# EFR32FG25A221F1920IM56 register map
Vendor: Silicon Labs; Series: EFR32; File version: B
Registers are 32-bit, read-write, reset 0x0 unless marked. A register's access mark holds for its fields unless they carry their own. Offsets are from the block's base; [hi:lo] are bit positions; {n}, {i} and the like mark numbered series.

## SMU_NS_CFGNS — SMU_NS_CFGNS Registers
Base 0x5400C000
Same registers: SMU_S_CFGNS 0x4400C000
0x04 NSSTATUS ro
  [0] SMUNSLOCK
    0=UNLOCKED; 1=LOCKED
0x08 NSLOCK wo
  [23:0] SMUNSLOCKKEY
    0xACCE55=UNLOCK (Unlocks Registers)
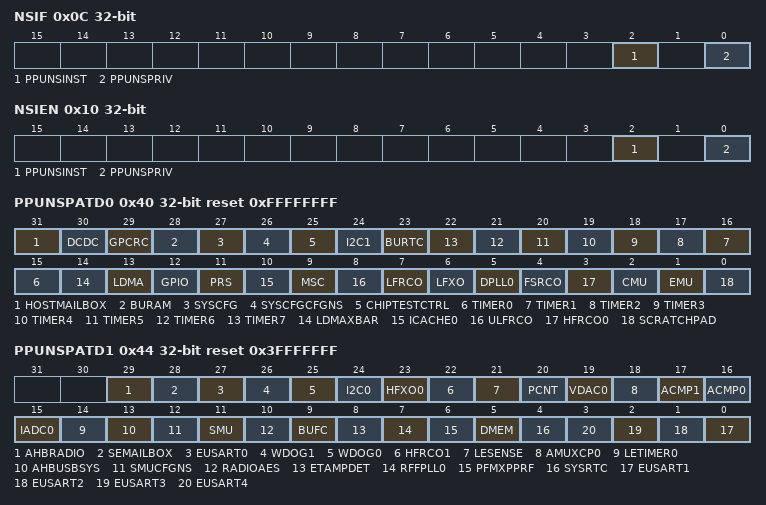
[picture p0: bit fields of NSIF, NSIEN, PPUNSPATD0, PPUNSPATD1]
0x0C NSIF
  [2] PPUNSINST — PPUNS Instruction Interrupt Flag
  [0] PPUNSPRIV — PPUNS Privilege Interrupt Flag
0x10 NSIEN
  [2] PPUNSINST — PPUNS Instruction Interrupt Enable
  [0] PPUNSPRIV — PPUNS Privilege Interrupt Enable
0x40 PPUNSPATD0 reset 0xFFFFFFFF — Set peripheral bits to 1 to mark as privileged access only
  [31] HOSTMAILBOX — HOSTMAILBOX Privileged Access
  [30] DCDC — DCDC Privileged Access
  [29] GPCRC — GPCRC Privileged Access
  [28] BURAM — BURAM Privileged Access
  [27] SYSCFG — SYSCFG Privileged Access
  [26] SYSCFGCFGNS — SYSCFGCFGNS Privileged Access
  [25] CHIPTESTCTRL — CHIPTESTCTRL Privileged Access
  [24] I2C1 — I2C1 Privileged Access
  [23] BURTC — BURTC Privileged Access
  [n+15] TIMER{n} (n=0..7) — TIMER{n} Privileged Access
  [14] LDMAXBAR — LDMAXBAR Privileged Access
  [13] LDMA — LDMA Privileged Access
  [12] GPIO — GPIO Privileged Access
  [11] PRS — PRS Privileged Access
  [10] ICACHE0 — ICACHE0 Privileged Access
  [9] MSC — MSC Privileged Access
  [8] ULFRCO — ULFRCO Privileged Access
  [7] LFRCO — LFRCO Privileged Access
  [6] LFXO — LFXO Privileged Access
  [5] DPLL0 — DPLL0 Privileged Access
  [4] FSRCO — FSRCO Privileged Access
  [3] HFRCO0 — HFRCO0 Privileged Access
  [2] CMU — CMU Privileged Access
  [1] EMU — EMU Privileged Access
  [0] SCRATCHPAD — SCRATCHPAD Privileged Access
0x44 PPUNSPATD1 reset 0x3FFFFFFF — Set peripheral bits to 1 to mark as privileged access only
  [29] AHBRADIO — AHBRADIO Privileged Access
  [28] SEMAILBOX — SEMAILBOX Privileged Access
  [27] EUSART0 — EUSART0 Privileged Access
  [26] WDOG1 — WDOG1 Privileged Access
  [25] WDOG0 — WDOG0 Privileged Access
  [24] I2C0 — I2C0 Privileged Access
  [23] HFXO0 — HFXO0 Privileged Access
  [22] HFRCO1 — HFRCO1 Privileged Access
  [21] LESENSE — LESENSE Privileged Access
  [20] PCNT — PCNT Privileged Access
  [19] VDAC0 — VDAC0 Privileged Access
  [18] AMUXCP0 — AMUXCP0 Privileged Access
  [17] ACMP1 — ACMP1 Privileged Access
  [16] ACMP0 — ACMP0 Privileged Access
  [15] IADC0 — IADC0 Privileged Access
  [14] LETIMER0 — LETIMER0 Privileged Access
  [13] AHBUSBSYS — AHBUSBSYS Privileged Access
  [12] SMUCFGNS — SMUCFGNS Privileged Access
  [11] SMU — SMU Privileged Access
  [10] RADIOAES — RADIOAES Privileged Access
  [9] BUFC — BUFC Privileged Access
  [8] ETAMPDET — ETAMPDET Privileged Access
  [7] RFFPLL0 — RFFPLL0 Privileged Access
  [6] PFMXPPRF — PFMXPPRF Privileged Access
  [5] DMEM — DMEM Privileged Access
  [4] SYSRTC — SYSRTC Privileged Access
  [n-1] EUSART{n} (n=1..4) — EUSART{n} Privileged Access
0x140 PPUNSFS ro
  [7:0] PPUFSPERIPHID — Peripheral I
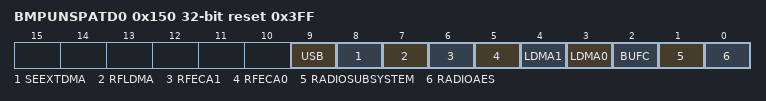
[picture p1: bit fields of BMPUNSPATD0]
0x150 BMPUNSPATD0 reset 0x3FF
  [9] USB — USB privileged mode
  [8] SEEXTDMA — SEEXTDMA privileged mode
  [7] RFLDMA — RFLDMA privileged mode
  [6] RFECA1 — RFECA1 privileged mode
  [5] RFECA0 — RFECA0 privileged mode
  [4] LDMA1 — MCU LDMA port 1 privileged mode
  [3] LDMA0 — MCU LDMA port 0 privileged mode
  [2] BUFC — BUFC privileged mode
  [1] RADIOSUBSYSTEM — RADIO subsystem manager privileged mode
  [0] RADIOAES — RADIO AES DMA privileged mode

## SYSCFG_NS_CFGNS — SYSCFG_NS_CFGNS Registers
Base 0x50078000
Same registers: SYSCFG_S_CFGNS 0x40078000
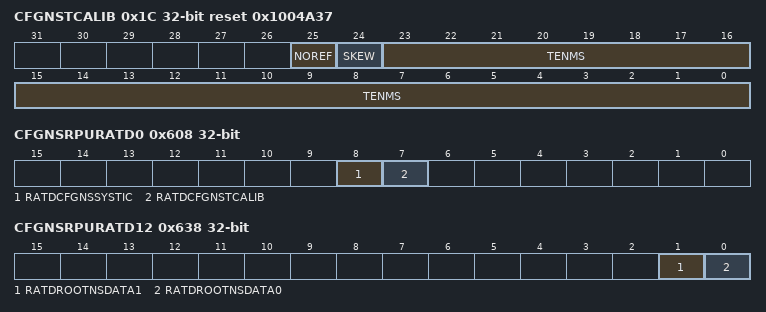
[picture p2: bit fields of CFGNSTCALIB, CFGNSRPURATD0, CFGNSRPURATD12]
0x1C CFGNSTCALIB reset 0x1004A37 — Configure to define the system tick for the M33.
  [25] NOREF — No Reference
    0=REF (Reference clock is implemented); 1=NOREF (Reference clock is not implemented)
  [24] SKEW
  [23:0] TENMS — Ten Milliseconds
0x600 ROOTNSDATA0 — Generic data space for user to pass to root, e.g., address of struct in mem
  [31:0] DATA
0x604 ROOTNSDATA1 — Generic data space for user to pass to root, e.g., address of struct in mem
  [31:0] DATA
0x608 CFGNSRPURATD0 — Protected register address = (RPURATD register index X 32 + RPURATD bit index) X 4.
  [8] RATDCFGNSSYSTIC — CFGNSSYSTIC Protection Bit
  [7] RATDCFGNSTCALIB — CFGNSTCALIB Protection Bit
0x638 CFGNSRPURATD12 — Protected register address = (RPURATD register index X 32 + RPURATD bit index) X 4.
  [1] RATDROOTNSDATA1 — DATA1 Protection Bit
  [0] RATDROOTNSDATA0 — DATA0 Protection Bit
